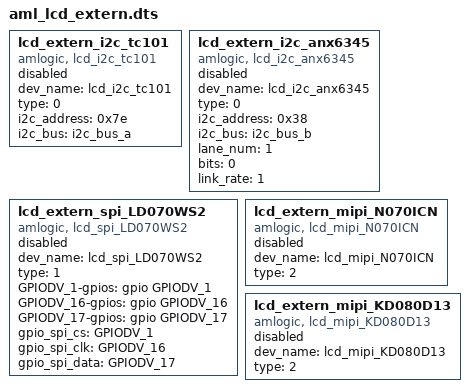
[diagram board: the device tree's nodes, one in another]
/* *************************************************************************
 * lcd extern
 * Notice: only one dev support
 * ************************************************************************* */
	lcd_extern_i2c_tc101{
		compatible = "amlogic, lcd_i2c_tc101";
		dev_name ="lcd_i2c_tc101";
		status = "disabled";

		type = <0>; /** lcd_extern_driver type: 0=i2c, 1=spi, 2=mipi */
		i2c_address = <0x7e>; /** i2c address */
		i2c_bus = "i2c_bus_a";
	};

	lcd_extern_i2c_anx6345{
		compatible = "amlogic, lcd_i2c_anx6345";
		dev_name ="lcd_i2c_anx6345";
		status = "disabled";

		type = <0>; /** lcd_extern_driver type: 0=i2c, 1=spi, 2=mipi */
		i2c_address = <0x38>; /** i2c address */
		i2c_bus = "i2c_bus_b";
		lane_num = <1>; /** edp lane_num: 1/2/4 */
		bits = <0>;  /** lcd_bits(0=6bit, 1=8bit) */
		link_rate = <1>; /** edp link rate: (0=1.62G, 1=27G, 2=5.4G) */
	};

	lcd_extern_spi_LD070WS2{
		compatible = "amlogic, lcd_spi_LD070WS2";
		dev_name ="lcd_spi_LD070WS2";
		status = "disabled";

		type = <1>; /** lcd_extern_driver type: 0=i2c, 1=spi, 2=mipi */
		GPIODV_1-gpios = <&gpio GPIODV_1 0>;
		GPIODV_16-gpios = <&gpio GPIODV_16 0>;
		GPIODV_17-gpios = <&gpio GPIODV_17 0>;
		gpio_spi_cs="GPIODV_1";
		gpio_spi_clk="GPIODV_16";
		gpio_spi_data="GPIODV_17";
	};

	lcd_extern_mipi_N070ICN{
		compatible = "amlogic, lcd_mipi_N070ICN";
		dev_name ="lcd_mipi_N070ICN";
		status = "disabled";

		type = <2>; /** lcd_extern_driver type: 0=i2c, 1=spi, 2=mipi */
	};

	lcd_extern_mipi_KD080D13{
		compatible = "amlogic, lcd_mipi_KD080D13";
		dev_name ="lcd_mipi_KD080D13";
		status = "disabled";

		type = <2>; /** lcd_extern_driver type: 0=i2c, 1=spi, 2=mipi */
	};
